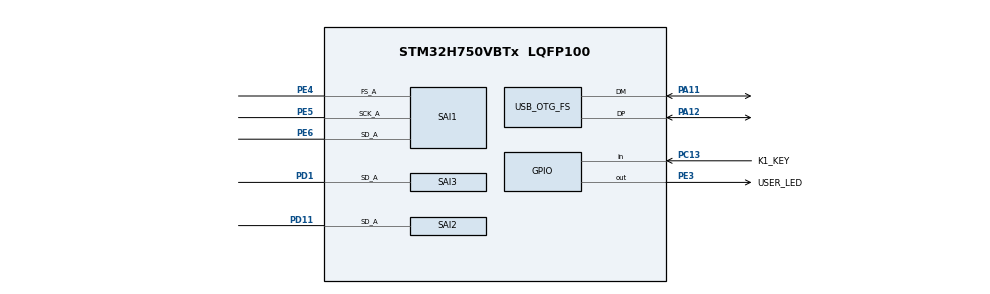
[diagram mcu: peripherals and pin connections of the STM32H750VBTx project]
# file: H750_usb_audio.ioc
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Dma.Request0=SAI1_A
Dma.Request1=SAI2_A
Dma.Request2=SAI3_A
Dma.SAI1_A.0.Direction=DMA_PERIPH_TO_MEMORY
Dma.SAI1_A.0.EventEnable=DISABLE
Dma.SAI1_A.0.FIFOMode=DMA_FIFOMODE_ENABLE
Dma.SAI1_A.0.FIFOThreshold=DMA_FIFO_THRESHOLD_FULL
Dma.SAI1_A.0.Instance=DMA1_Stream1
Dma.SAI1_A.0.MemBurst=DMA_MBURST_SINGLE
Dma.SAI1_A.0.MemDataAlignment=DMA_MDATAALIGN_HALFWORD
Dma.SAI1_A.0.MemInc=DMA_MINC_ENABLE
Dma.SAI1_A.0.Mode=DMA_NORMAL
Dma.SAI1_A.0.PeriphBurst=DMA_PBURST_SINGLE
Dma.SAI1_A.0.PeriphDataAlignment=DMA_PDATAALIGN_HALFWORD
Dma.SAI1_A.0.PeriphInc=DMA_PINC_DISABLE
Dma.SAI1_A.0.Polarity=HAL_DMAMUX_REQ_GEN_RISING
Dma.SAI1_A.0.Priority=DMA_PRIORITY_LOW
Dma.SAI1_A.0.RequestNumber=1
Dma.SAI1_A.0.SignalID=NONE
Dma.SAI1_A.0.SyncEnable=DISABLE
Dma.SAI1_A.0.SyncPolarity=HAL_DMAMUX_SYNC_NO_EVENT
Dma.SAI1_A.0.SyncRequestNumber=1
Dma.SAI1_A.0.SyncSignalID=NONE
Dma.SAI2_A.1.Direction=DMA_PERIPH_TO_MEMORY
Dma.SAI2_A.1.EventEnable=DISABLE
Dma.SAI2_A.1.FIFOMode=DMA_FIFOMODE_ENABLE
Dma.SAI2_A.1.FIFOThreshold=DMA_FIFO_THRESHOLD_FULL
Dma.SAI2_A.1.Instance=DMA1_Stream2
Dma.SAI2_A.1.MemBurst=DMA_MBURST_SINGLE
Dma.SAI2_A.1.MemDataAlignment=DMA_MDATAALIGN_HALFWORD
Dma.SAI2_A.1.MemInc=DMA_MINC_ENABLE
Dma.SAI2_A.1.Mode=DMA_NORMAL
Dma.SAI2_A.1.PeriphBurst=DMA_PBURST_SINGLE
Dma.SAI2_A.1.PeriphDataAlignment=DMA_PDATAALIGN_HALFWORD
Dma.SAI2_A.1.PeriphInc=DMA_PINC_DISABLE
Dma.SAI2_A.1.Polarity=HAL_DMAMUX_REQ_GEN_RISING
Dma.SAI2_A.1.Priority=DMA_PRIORITY_LOW
Dma.SAI2_A.1.RequestNumber=1
Dma.SAI2_A.1.SignalID=NONE
Dma.SAI2_A.1.SyncEnable=DISABLE
Dma.SAI2_A.1.SyncPolarity=HAL_DMAMUX_SYNC_NO_EVENT
Dma.SAI2_A.1.SyncRequestNumber=1
Dma.SAI2_A.1.SyncSignalID=NONE
Dma.SAI3_A.2.Direction=DMA_PERIPH_TO_MEMORY
Dma.SAI3_A.2.EventEnable=DISABLE
Dma.SAI3_A.2.FIFOMode=DMA_FIFOMODE_ENABLE
Dma.SAI3_A.2.FIFOThreshold=DMA_FIFO_THRESHOLD_FULL
Dma.SAI3_A.2.Instance=DMA1_Stream3
Dma.SAI3_A.2.MemBurst=DMA_MBURST_SINGLE
Dma.SAI3_A.2.MemDataAlignment=DMA_MDATAALIGN_HALFWORD
Dma.SAI3_A.2.MemInc=DMA_MINC_ENABLE
Dma.SAI3_A.2.Mode=DMA_NORMAL
Dma.SAI3_A.2.PeriphBurst=DMA_PBURST_SINGLE
Dma.SAI3_A.2.PeriphDataAlignment=DMA_PDATAALIGN_HALFWORD
Dma.SAI3_A.2.PeriphInc=DMA_PINC_DISABLE
Dma.SAI3_A.2.Polarity=HAL_DMAMUX_REQ_GEN_RISING
Dma.SAI3_A.2.Priority=DMA_PRIORITY_LOW
Dma.SAI3_A.2.RequestNumber=1
Dma.SAI3_A.2.SignalID=NONE
Dma.SAI3_A.2.SyncEnable=DISABLE
Dma.SAI3_A.2.SyncPolarity=HAL_DMAMUX_SYNC_NO_EVENT
Dma.SAI3_A.2.SyncRequestNumber=1
Dma.SAI3_A.2.SyncSignalID=NONE
Mcu.Family=STM32H7
Mcu.Name=STM32H750VBTx
Mcu.Package=LQFP100
NVIC.DMA1_Stream1_IRQn=true\:0\:0\:false\:false\:true\:false\:true\:true
NVIC.DMA1_Stream2_IRQn=true\:0\:0\:false\:false\:true\:false\:true\:true
NVIC.DMA1_Stream3_IRQn=true\:0\:0\:false\:false\:true\:false\:true\:true
NVIC.OTG_FS_EP1_IN_IRQn=true\:0\:0\:false\:false\:true\:false\:true\:true
NVIC.OTG_FS_EP1_OUT_IRQn=true\:0\:0\:false\:false\:true\:false\:true\:true
NVIC.OTG_FS_IRQn=true\:0\:0\:false\:false\:true\:true\:true\:true
NVIC.PriorityGroup=NVIC_PRIORITYGROUP_4
PA11.Mode=Device_Only
PA11.Signal=USB_OTG_FS_DM
PA12.Mode=Device_Only
PA12.Signal=USB_OTG_FS_DP
PA13\ (JTMS/SWDIO).Mode=Serial_Wire
PA13\ (JTMS/SWDIO).Signal=DEBUG_JTMS-SWDIO
PA14\ (JTCK/SWCLK).Mode=Serial_Wire
PA14\ (JTCK/SWCLK).Signal=DEBUG_JTCK-SWCLK
PC13.GPIO_Label=K1_KEY
PC13.GPIO_PuPd=GPIO_PULLDOWN
PC13.Signal=GPIO_Input
PC14-OSC32_IN\ (OSC32_IN).Mode=LSE-External-Oscillator
PC14-OSC32_IN\ (OSC32_IN).Signal=RCC_OSC32_IN
PC15-OSC32_OUT\ (OSC32_OUT).Mode=LSE-External-Oscillator
PC15-OSC32_OUT\ (OSC32_OUT).Signal=RCC_OSC32_OUT
PD1.Mode=SAI_A_SyncSlave
PD1.Signal=SAI3_SD_A
PD11.Mode=SAI_A_SyncSlave
PD11.Signal=SAI2_SD_A
PE3.GPIO_Label=USER_LED
PE3.GPIO_PuPd=GPIO_PULLDOWN
PE3.GPIO_Speed=GPIO_SPEED_FREQ_MEDIUM
PE3.PinState=GPIO_PIN_SET
PE3.Signal=GPIO_Output
PE4.Mode=SAI_A_Master
PE4.Signal=SAI1_FS_A
PE5.Mode=SAI_A_Master
PE5.Signal=SAI1_SCK_A
PE6.Mode=SAI_A_Master
PE6.Signal=SAI1_SD_A
PH0-OSC_IN\ (PH0).Mode=HSE-External-Oscillator
PH0-OSC_IN\ (PH0).Signal=RCC_OSC_IN
PH1-OSC_OUT\ (PH1).Mode=HSE-External-Oscillator
PH1-OSC_OUT\ (PH1).Signal=RCC_OSC_OUT
ProjectManager.HeapSize=0x4000
ProjectManager.StackSize=0x4000
ProjectManager.TargetToolchain=STM32CubeIDE
RCC.ADCFreq_Value=50390625
RCC.APB1Freq_Value=120000000
RCC.APB2Freq_Value=120000000
RCC.APB3Freq_Value=120000000
RCC.APB4Freq_Value=120000000
RCC.CortexFreq_Value=480000000
RCC.D1PPRE=RCC_APB3_DIV2
RCC.D2PPRE1=RCC_APB1_DIV2
RCC.D2PPRE2=RCC_APB2_DIV2
RCC.D3PPRE=RCC_APB4_DIV2
RCC.DIVM1=5
RCC.DIVN1=192
RCC.DIVQ1=15
RCC.DIVQ3=102
RCC.EnbaleCSS=true
RCC.HCLKFreq_Value=240000000
RCC.HPRE=RCC_HCLK_DIV2
RCC.HSE_VALUE=25000000
RCC.PLL2FRACN=0
RCC.PLLFRACN=0
RCC.PLLSourceVirtual=RCC_PLLSOURCE_HSE
RCC.SYSCLKFreq_VALUE=480000000
RCC.SYSCLKSource=RCC_SYSCLKSOURCE_PLLCLK
RCC.USBCLockSelection=RCC_USBCLKSOURCE_HSI48
RCC.USBFreq_Value=48000000
SAI1.AudioFrequency-SAI_A_Master=SAI_AUDIO_FREQUENCY_48K
SAI1.AudioMode-SAI_A_Master=SAI_MODEMASTER_RX
SAI1.ErrorAudioFreq-SAI_A_Master=30.2 %
SAI1.Instance-SAI_A_Master=SAI$Index_Block_A
SAI1.MClockEnable=SAI_MASTERCLOCK_DISABLE
SAI1.RealAudioFreq-SAI_A_Master=62.5 KHz
SAI1.VirtualMode-SAI_A_Master=VM_MASTER
SAI2.Instance-SAI_A_SyncSlave=SAI$Index_Block_A
SAI2.VirtualMode-SAI_A_SyncSlave=VM_SLAVE
SAI3.Instance-SAI_A_SyncSlave=SAI$Index_Block_A
SAI3.VirtualMode-SAI_A_SyncSlave=VM_SLAVE
USB_DEVICE.CLASS_NAME_FS=AUDIO
USB_DEVICE.USBD_AUDIO_FREQ-AUDIO_FS=48000
USB_DEVICE.USBD_DEBUG_LEVEL-AUDIO_FS=3
USB_DEVICE.USBD_SELF_POWERED-AUDIO_FS=0
USB_DEVICE.VirtualMode-AUDIO_FS=Audio
USB_DEVICE.VirtualMode-CDC_FS=Cdc
USB_DEVICE.VirtualModeFS=Audio_FS
USB_OTG_FS.Sof_enable=DISABLE
USB_OTG_FS.VirtualMode=Device_Only
USB_OTG_FS.battery_charging_enable=DISABLE
USB_OTG_FS.dma_enable=DISABLE
USB_OTG_FS.use_dedicated_ep1=ENABLE
VP_RCC_USB.Mode=USB_FS
VP_USB_DEVICE_VS_USB_DEVICE_AUDIO_FS.Mode=AUDIO_FS
board=custom

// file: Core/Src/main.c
/* USER CODE BEGIN Header */
/**
  ******************************************************************************
  * @file           : main.c
  * @brief          : Main program body
  ******************************************************************************
  * @attention
  *
  * Copyright (c) 2022 STMicroelectronics.
  * All rights reserved.
  *
  * This software is licensed under terms that can be found in the LICENSE file
  * in the root directory of this software component.
  * If no LICENSE file comes with this software, it is provided AS-IS.
  *
  ******************************************************************************
  */
/* USER CODE END Header */
#include "main.h"
#include "dma.h"
#include "sai.h"
#include "usb_device.h"
#include "gpio.h"

void SystemClock_Config(void);

int main(void)
{

  /* MCU Configuration--------------------------------------------------------*/

  /* Reset of all peripherals, Initializes the Flash interface and the Systick. */
  HAL_Init();

  /* Configure the system clock */
  SystemClock_Config();

  /* Initialize all configured peripherals */
  MX_GPIO_Init();
  MX_DMA_Init();
  MX_SAI1_Init();
  MX_USB_DEVICE_Init();
  MX_SAI3_Init();
  MX_SAI2_Init();

  /* Infinite loop */
  while (1)
  {

  }
}

void SystemClock_Config(void)
{
  RCC_OscInitTypeDef RCC_OscInitStruct = {0};
  RCC_ClkInitTypeDef RCC_ClkInitStruct = {0};
  RCC_CRSInitTypeDef RCC_CRSInitStruct = {0};

  /** Supply configuration update enable
  */
  HAL_PWREx_ConfigSupply(PWR_LDO_SUPPLY);

  /** Configure the main internal regulator output voltage
  */
  __HAL_PWR_VOLTAGESCALING_CONFIG(PWR_REGULATOR_VOLTAGE_SCALE0);

  while(!__HAL_PWR_GET_FLAG(PWR_FLAG_VOSRDY)) {}

  /** Initializes the RCC Oscillators according to the specified parameters
  * in the RCC_OscInitTypeDef structure.
  */
  RCC_OscInitStruct.OscillatorType = RCC_OSCILLATORTYPE_HSI48|RCC_OSCILLATORTYPE_HSE;
  RCC_OscInitStruct.HSEState = RCC_HSE_ON;
  RCC_OscInitStruct.HSI48State = RCC_HSI48_ON;
  RCC_OscInitStruct.PLL.PLLState = RCC_PLL_ON;
  RCC_OscInitStruct.PLL.PLLSource = RCC_PLLSOURCE_HSE;
  RCC_OscInitStruct.PLL.PLLM = 5;
  RCC_OscInitStruct.PLL.PLLN = 192;
  RCC_OscInitStruct.PLL.PLLP = 2;
  RCC_OscInitStruct.PLL.PLLQ = 15;
  RCC_OscInitStruct.PLL.PLLR = 2;
  RCC_OscInitStruct.PLL.PLLRGE = RCC_PLL1VCIRANGE_2;
  RCC_OscInitStruct.PLL.PLLVCOSEL = RCC_PLL1VCOWIDE;
  RCC_OscInitStruct.PLL.PLLFRACN = 0;
  if (HAL_RCC_OscConfig(&RCC_OscInitStruct) != HAL_OK)
  {
    Error_Handler();
  }

  /** Initializes the CPU, AHB and APB buses clocks
  */
  RCC_ClkInitStruct.ClockType = RCC_CLOCKTYPE_HCLK|RCC_CLOCKTYPE_SYSCLK
                              |RCC_CLOCKTYPE_PCLK1|RCC_CLOCKTYPE_PCLK2
                              |RCC_CLOCKTYPE_D3PCLK1|RCC_CLOCKTYPE_D1PCLK1;
  RCC_ClkInitStruct.SYSCLKSource = RCC_SYSCLKSOURCE_PLLCLK;
  RCC_ClkInitStruct.SYSCLKDivider = RCC_SYSCLK_DIV1;
  RCC_ClkInitStruct.AHBCLKDivider = RCC_HCLK_DIV2;
  RCC_ClkInitStruct.APB3CLKDivider = RCC_APB3_DIV2;
  RCC_ClkInitStruct.APB1CLKDivider = RCC_APB1_DIV2;
  RCC_ClkInitStruct.APB2CLKDivider = RCC_APB2_DIV2;
  RCC_ClkInitStruct.APB4CLKDivider = RCC_APB4_DIV2;

  if (HAL_RCC_ClockConfig(&RCC_ClkInitStruct, FLASH_LATENCY_4) != HAL_OK)
  {
    Error_Handler();
  }

  /** Enables the Clock Security System
  */
  HAL_RCC_EnableCSS();

  /** Enable the SYSCFG APB clock
  */
  __HAL_RCC_CRS_CLK_ENABLE();

  /** Configures CRS
  */
  RCC_CRSInitStruct.Prescaler = RCC_CRS_SYNC_DIV1;
  RCC_CRSInitStruct.Source = RCC_CRS_SYNC_SOURCE_USB2;
  RCC_CRSInitStruct.Polarity = RCC_CRS_SYNC_POLARITY_RISING;
  RCC_CRSInitStruct.ReloadValue = __HAL_RCC_CRS_RELOADVALUE_CALCULATE(48000000,1000);
  RCC_CRSInitStruct.ErrorLimitValue = 34;
  RCC_CRSInitStruct.HSI48CalibrationValue = 32;

  HAL_RCCEx_CRSConfig(&RCC_CRSInitStruct);
}

void Error_Handler(void)
{
  /* USER CODE BEGIN Error_Handler_Debug */
  /* User can add his own implementation to report the HAL error return state */
  __disable_irq();
  while (1)
  {
	  printf("usb startup error!!!!!\n");

  }
  /* USER CODE END Error_Handler_Debug */
}
